# MM32F103xx register map
File version: 1.08
Registers are 32-bit, read-write, reset 0x0 unless marked. A register's access mark holds for its fields unless they carry their own. Offsets are from the block's base; [hi:lo] are bit positions; {n}, {i} and the like mark numbered series; 'fields as' and 'values as' point back to an identical list.

## CRC — CRC calculation unit
Base 0x40023000
0x00 DR reset 0xFFFF — Data register
  [31:0] DR — Data register bits
0x04 IDR — Independent data register
  [7:0] IDR — General-purpose 8-bit data register bits
0x08 CTRL wo — Control register
  [0] RESET — CRC reset

## DBG — Debug support
Base 0x40007080
0x00 IDCODE ro
  [31:0] DEV_ID — *D0
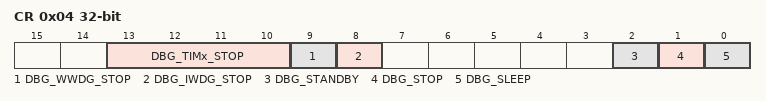
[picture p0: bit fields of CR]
0x04 CR wo
  [13:10] DBG_TIMx_STOP — TIMx counter stopped when core is halted
  [9] DBG_WWDG_STOP — Debug window watchdog when core is halted
  [8] DBG_IWDG_STOP — Debug independent watchdog stopped when core is stopped
  [2] DBG_STANDBY — Debug Standby mode
  [1] DBG_STOP — Debug Stop mode
  [0] DBG_SLEEP — Device identifier

## DMA1 — DMA1 controller
Base 0x40020000
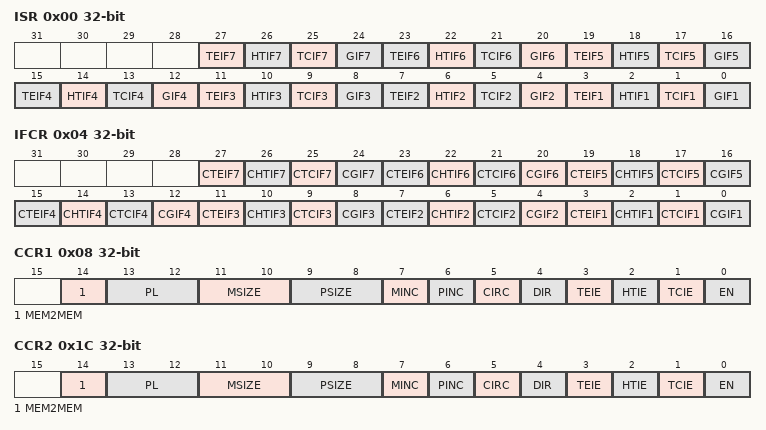
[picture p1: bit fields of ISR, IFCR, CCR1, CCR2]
0x00 ISR ro
  [4n-1] TEIF{n} (n=1..7) — channel {n} transfer error flag
  [4n-2] HTIF{n} (n=1..7) — channel {n} half transfer flag
  [4n-3] TCIF{n} (n=1..7) — channel {n} transfer complete flag
  [4n-4] GIF{n} (n=1..7) — channel {n} global interrupt flag
0x04 IFCR
  [4n-1] CTEIF{n} (n=1..7) — channel {n} transfer error clear
  [4n-2] CHTIF{n} (n=1..7) — channel {n} half transfer clear
  [4n-3] CTCIF{n} (n=1..7) — channel {n} transfer complete clear
  [4n-4] CGIF{n} (n=1..7) — channel {n} global interrupt clear
0x08 CCR1
  [14] MEM2MEM — Memory to memory mode
  [13:12] PL — Channel priority level
  [11:10] MSIZE — Memory size
  [9:8] PSIZE — Peripheral size
  [7] MINC — Memory increment mode
  [6] PINC — Peripheral increment mode
  [5] CIRC — Circular mode
  [4] DIR — Data transfer direction
  [3] TEIE — Transfer error interrupt enable
  [2] HTIE — Half transfer interrupt enable
  [1] TCIE — Transfer complete interrupt enable
  [0] EN — Channel enable
0x0C CNDTR1
  [15:0] NDT — Number of data to transfer
0x10 CPAR1
  [31:0] PA — Peripheral address
{0x0+0x14*i} CMAR{i} (i=1..7)
  [31:0] MA — Memory address
0x1C CCR2
  fields as CCR1
0x20 CNDTR2
  [15:0] NDT — Number of data to transfer
0x24 CPAR2
  [31:0] PA — Peripheral address
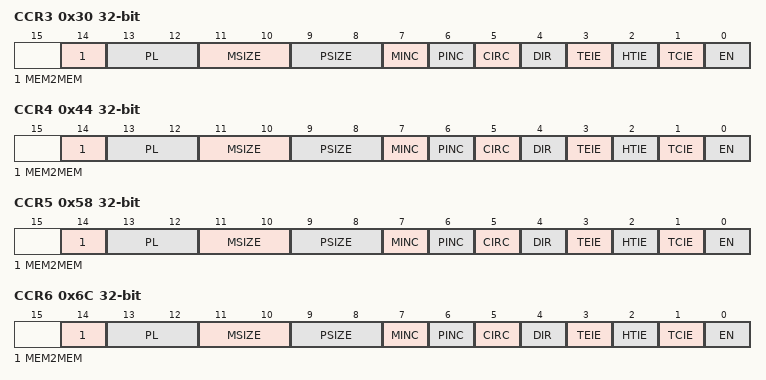
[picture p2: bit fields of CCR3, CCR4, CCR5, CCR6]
0x30 CCR3
  fields as CCR1
0x34 CNDTR3
  [15:0] NDT — Number of data to transfer
0x38 CPAR3
  [31:0] PA — Peripheral address
0x44 CCR4
  fields as CCR1
0x48 CNDTR4
  [15:0] NDT — Number of data to transfer
0x4C CPAR4
  [31:0] PA — Peripheral address
0x58 CCR5
  fields as CCR1
0x5C CNDTR5
  [15:0] NDT — Number of data to transfer
0x60 CPAR5
  [31:0] PA — Peripheral address
0x6C CCR6
  fields as CCR1
0x70 CNDTR6
  [15:0] NDT — Number of data to transfer
0x74 CPAR6
  [31:0] PA — Peripheral address
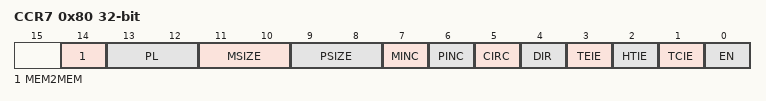
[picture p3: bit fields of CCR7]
0x80 CCR7
  fields as CCR1
0x84 CNDTR7
  [15:0] NDT — Number of data to transfer
0x88 CPAR7
  [31:0] PA — Peripheral address

## EXTI — External interrupt/event controller
Base 0x40010400
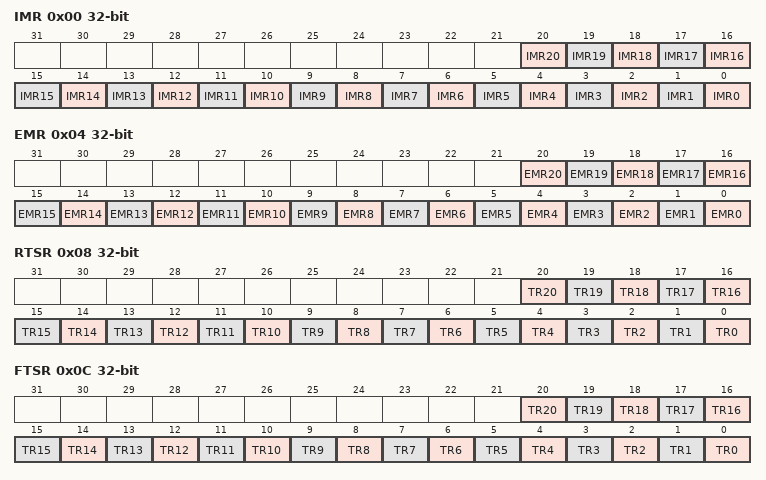
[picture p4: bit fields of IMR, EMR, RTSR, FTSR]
0x00 IMR — Interrupt mask register
  [n] IMR{n} (n=0..20) — Interrupt Mask on line {n}
0x04 EMR — Event mask register
  [n] EMR{n} (n=0..20) — Event Mask on line {n}
0x08 RTSR — Rising trigger selection register
  [n] TR{n} (n=0..20) — Rising trigger event configuration bit of line {n}
0x0C FTSR — Falling trigger selection register
  [n] TR{n} (n=0..20) — Falling trigger event configuration bit of line {n}
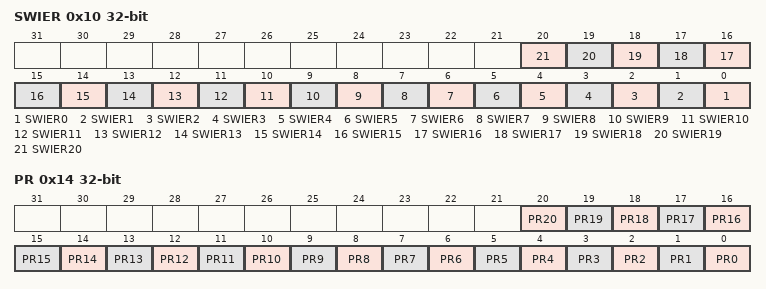
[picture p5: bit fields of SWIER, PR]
0x10 SWIER — Software interrupt event register
  [n] SWIER{n} (n=0..20) — Software interrupt on line {n}
0x14 PR — Pending register
  [n] PR{n} (n=0..20) — Pending bit

## FLASH
Base 0x40022000
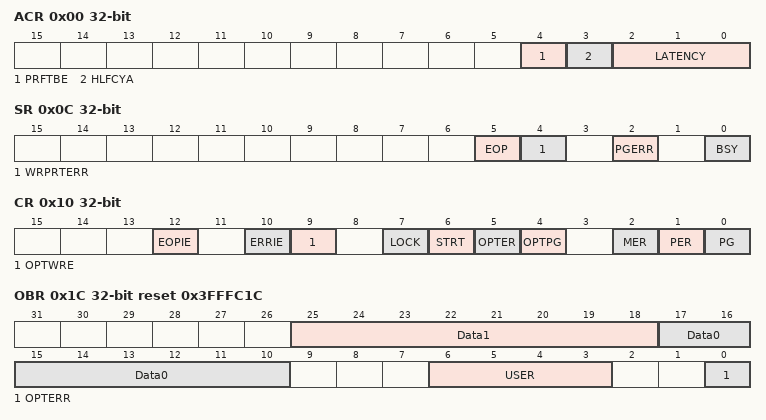
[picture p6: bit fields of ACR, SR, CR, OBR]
0x00 ACR — Flash access control register
  [4] PRFTBE — Prefetch buffer enable
  [3] HLFCYA — Flash half cycle access enable
  [2:0] LATENCY
0x04 KEYR wo — Flash key
  [31:0] FKEYR
0x08 OPTKEYR wo — Option byte key
0x0C SR — Flash status register
  [5] EOP — End of operation
  [4] WRPRTERR — Write protection error
  [2] PGERR — Programming error
  [0] BSY — Busy
0x10 CR — Flash control register
  [12] EOPIE — End of operation interrupt enable
  [10] ERRIE — Error interrupt enable
  [9] OPTWRE — Option byte write enable
  [7] LOCK
  [6] STRT — Start
  [5] OPTER — Option byte erase
  [4] OPTPG — Option byte programming
  [2] MER — Mass erase
  [1] PER — Page erase
  [0] PG — Programming
0x14 AR wo — Flash address register
  [31:0] FAR — Flash Address
0x1C OBR ro reset 0x3FFFC1C — Option byte register
  [25:18] Data1
  [17:10] Data0
  [6:3] USER — Uesr option bytes
  [0] OPTERR — Option byte error
0x20 WRPR ro reset 0xFFFFFFFF — Write protect register
  [31:0] WRP — Write protect
